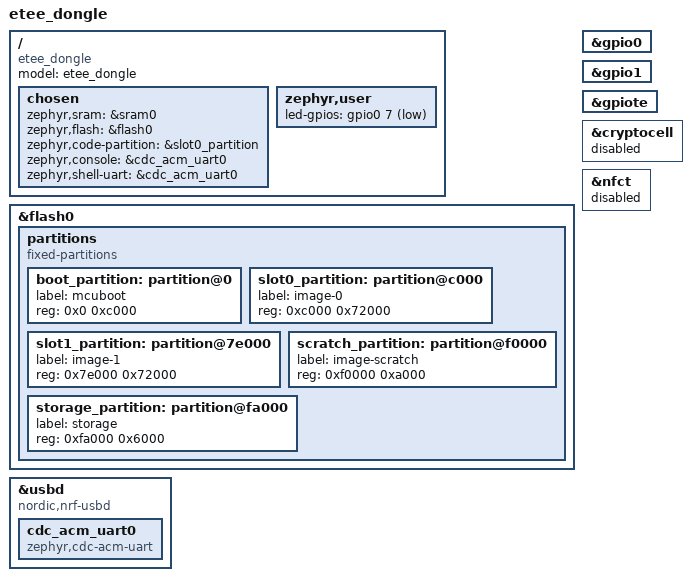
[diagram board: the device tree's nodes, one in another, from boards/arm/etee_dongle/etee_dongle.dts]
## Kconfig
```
#
# Copyright (c) 2020 Nordic Semiconductor
#
# SPDX-License-Identifier: LicenseRef-Nordic-5-Clause
#

source "Kconfig.zephyr"

menu "SlimeNRF"

endmenu
```

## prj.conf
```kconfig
#
# Copyright (c) 2019 Nordic Semiconductor ASA
#
# SPDX-License-Identifier: LicenseRef-Nordic-5-Clause
#
CONFIG_NCS_SAMPLES_DEFAULTS=y
CONFIG_ESB=y
CONFIG_NEWLIB_LIBC=y
CONFIG_CBPRINTF_FP_SUPPORT=y

CONFIG_USB_DEVICE_STACK=y
CONFIG_USB_DEVICE_HID=y
CONFIG_USB_DEVICE_MANUFACTURER="SlimeVR"
CONFIG_USB_DEVICE_VID=0x1209
CONFIG_USB_DEVICE_PID=0x7690
CONFIG_USB_HID_BOOT_PROTOCOL=y
CONFIG_USB_DEVICE_INITIALIZE_AT_BOOT=n
CONFIG_USB_CDC_ACM=y
CONFIG_UART_INTERRUPT_DRIVEN=y 

CONFIG_SERIAL=y
CONFIG_CONSOLE=y
CONFIG_UART_CONSOLE=y
CONFIG_UART_LINE_CTRL=y

CONFIG_LOG=y
CONFIG_USB_DRIVER_LOG_LEVEL_WRN=y
CONFIG_USB_DEVICE_LOG_LEVEL_WRN=y

CONFIG_LOG_BACKEND_UART=y
CONFIG_LOG_MODE_DEFERRED=y
#CONFIG_LOG_MODE_IMMEDIATE=y

CONFIG_CONSOLE_SUBSYS=y
CONFIG_CONSOLE_GETLINE=y

CONFIG_NVS_LOG_LEVEL_WRN=y
CONFIG_USB_HID_LOG_LEVEL_WRN=y

CONFIG_USB_DEVICE_SOF=y
CONFIG_USB_HID_REPORTS=256

#CONFIG_USB_HID_POLL_INTERVAL_MS=1
CONFIG_USB_HID_POLL_INTERVAL_MS=0
CONFIG_HID_INTERRUPT_EP_MPS=64
#CONFIG_ENABLE_HID_INT_OUT_EP=y

CONFIG_GPIO=y

CONFIG_NVS=y

CONFIG_FLASH=y
CONFIG_FLASH_PAGE_LAYOUT=y
CONFIG_FLASH_MAP=y

CONFIG_SETTINGS=y
CONFIG_SETTINGS_NVS=y
CONFIG_SETTINGS_RUNTIME=y

CONFIG_MPU_ALLOW_FLASH_WRITE=y

CONFIG_NVS_LOOKUP_CACHE=y

CONFIG_ESB_TX_FIFO_SIZE=1
CONFIG_NRFX_TIMER1=y

#speed up boot? (use internal rc oscillator)
#CONFIG_CLOCK_CONTROL_NRF_K32SRC_RC=y
#speed up boot? (synthesize lf clock)
CONFIG_CLOCK_CONTROL_NRF_K32SRC_SYNTH=y

# dont need it
CONFIG_CRYPTO=n
```

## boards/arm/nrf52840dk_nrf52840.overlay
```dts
/ {
	zephyr,user {
		led-gpios = <&gpio0 13 (GPIO_ACTIVE_LOW | GPIO_OPEN_DRAIN)>;
	};
};
```

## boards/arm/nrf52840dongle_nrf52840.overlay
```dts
/ {
	zephyr,user {
		led-gpios = <&gpio0 6 (GPIO_ACTIVE_LOW | GPIO_OPEN_DRAIN)>;
	};
};
```

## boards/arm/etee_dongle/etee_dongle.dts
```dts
// Copyright (c) 2024 Nordic Semiconductor ASA
// SPDX-License-Identifier: Apache-2.0

/dts-v1/;
#include <nordic/nrf52840_qiaa.dtsi>

/ {
	model = "etee_dongle";
	compatible = "etee_dongle";

	chosen {
		zephyr,sram = &sram0;
		zephyr,flash = &flash0;
		zephyr,code-partition = &slot0_partition;
		zephyr,console = &cdc_acm_uart0;
		zephyr,shell-uart = &cdc_acm_uart0;
	};

	zephyr,user {
		led-gpios = <&gpio0 7 (GPIO_ACTIVE_LOW | GPIO_OPEN_DRAIN)>;
		// red 0.07, green 1.15, blue 1.09
	};
};

&flash0 {
	partitions {
		compatible = "fixed-partitions";
		#address-cells = <1>;
		#size-cells = <1>;

		boot_partition: partition@0 {
			label = "mcuboot";
			reg = <0x0 0xc000>;
		};
		slot0_partition: partition@c000 {
			label = "image-0";
			reg = <0xc000 0x72000>;
		};
		slot1_partition: partition@7e000 {
			label = "image-1";
			reg = <0x7e000 0x72000>;
		};
		scratch_partition: partition@f0000 {
			label = "image-scratch";
			reg = <0xf0000 0xa000>;
		};
		storage_partition: partition@fa000 {
			label = "storage";
			reg = <0xfa000 0x6000>;
		};
	};
};

&gpio0 {
	status = "okay";
};

&gpio1 {
	status = "okay";
};

&gpiote {
	status = "okay";
};

zephyr_udc0: &usbd {
	compatible = "nordic,nrf-usbd";
	status = "okay";
	cdc_acm_uart0: cdc_acm_uart0 {
		compatible = "zephyr,cdc-acm-uart";
	};
};

&cryptocell {
	status = "disabled";
};

&nfct {
	status = "disabled";
};
```

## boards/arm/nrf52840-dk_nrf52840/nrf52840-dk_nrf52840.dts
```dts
// Copyright (c) 2024 Nordic Semiconductor ASA
// SPDX-License-Identifier: Apache-2.0

/dts-v1/;
#include <nordic/nrf52840_qiaa.dtsi>

/ {
	model = "nrf52840-dk_nrf52840";
	compatible = "nrf52840-dk_nrf52840";

	chosen {
		zephyr,sram = &sram0;
		zephyr,flash = &flash0;
		zephyr,code-partition = &slot0_partition;
	};

	zephyr,user {
		led-gpios = <&gpio0 13 (GPIO_ACTIVE_LOW | GPIO_OPEN_DRAIN)>;
	};
};

&flash0 {
	partitions {
		compatible = "fixed-partitions";
		#address-cells = <1>;
		#size-cells = <1>;

		// use original partitioning to keep nvs
		boot_partition: partition@0 {
			label = "mcuboot";
			reg = <0x00000000 0x0000C000>;
		};
		slot0_partition: partition@c000 {
			label = "image-0";
			reg = <0x0000C000 0x00076000>;
		};
		slot1_partition: partition@82000 {
			label = "image-1";
			reg = <0x00082000 0x00076000>;
		};
		storage_partition: partition@f8000 {
			label = "storage";
			reg = <0x000f8000 0x00008000>;
		};
	};
};

&usbd {
	status = "okay";
};

&gpio0 {
	status = "okay";
};

&gpiote {
	status = "okay";
};
```

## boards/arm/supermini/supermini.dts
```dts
// Copyright (c) 2024 Nordic Semiconductor ASA
// SPDX-License-Identifier: Apache-2.0

/dts-v1/;
#include <nordic/nrf52840_qiaa.dtsi>

/ {
	model = "supermini";
	compatible = "supermini";

	chosen {
		zephyr,sram = &sram0;
		zephyr,flash = &flash0;
		zephyr,code-partition = &slot0_partition;
		zephyr,console = &cdc_acm_uart0;
		zephyr,shell-uart = &cdc_acm_uart0;
	};

	// Uncomment below to Enable SW0
	// buttons {
	// 	compatible = "gpio-keys";
	// 	button0: button_0 {
	// 		gpios = <&gpio0 20 (GPIO_PULL_UP | GPIO_ACTIVE_LOW)>;
	// 		label = "Push button switch 0";
	// 	};
	// };

	// aliases {
	// 	sw0 = &button0;
	// };

	zephyr,user {
		led-gpios = <&gpio0 15 GPIO_OPEN_SOURCE>;
	};
};

&flash0 {
	partitions {
		compatible = "fixed-partitions";
		#address-cells = <1>;
		#size-cells = <1>;

		boot_partition: partition@0 {
			label = "mcuboot";
			reg = <0x0 0xc000>;
		};
		slot0_partition: partition@c000 {
			label = "image-0";
			reg = <0xc000 0x72000>;
		};
		slot1_partition: partition@7e000 {
			label = "image-1";
			reg = <0x7e000 0x72000>;
		};
		scratch_partition: partition@f0000 {
			label = "image-scratch";
			reg = <0xf0000 0xa000>;
		};
		storage_partition: partition@fa000 {
			label = "storage";
			reg = <0xfa000 0x6000>;
		};
	};
};

&gpio0 {
	status = "okay";
};

&gpiote {
	status = "okay";
};

zephyr_udc0: &usbd {
	compatible = "nordic,nrf-usbd";
	status = "okay";
	cdc_acm_uart0: cdc_acm_uart0 {
		compatible = "zephyr,cdc-acm-uart";
	};
};

&cryptocell {
	status = "disabled";
};

&nfct {
	status = "disabled";
};
```

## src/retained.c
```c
/*
 * Copyright (c) 2021 Nordic Semiconductor ASA
 *
 * SPDX-License-Identifier: Apache-2.0
 */

#include <string.h>
#include <zephyr/kernel.h>
#include <zephyr/devicetree.h>
#include <zephyr/sys/byteorder.h>
#include <zephyr/sys/crc.h>
#include <hal/nrf_power.h>
#include "retained.h"

/* nRF52 RAM (really, RAM AHB slaves) are partitioned as:
 * * Up to 8 blocks of two 4 KiBy byte "small" sections
 * * A 9th block of with 32 KiBy "large" sections
 *
 * At time of writing the maximum number of large sections is 6, all
 * within the first large block.  Theoretically there could be more
 * sections in the 9th block, and possibly more blocks.
 */

/* Inclusive address of RAM start */
#define SRAM_BEGIN (uintptr_t)DT_REG_ADDR(DT_NODELABEL(sram0))

/* Exclusive address of RAM end */
#define SRAM_END (SRAM_BEGIN + (uintptr_t)DT_REG_SIZE(DT_NODELABEL(sram0)))

/* Size of a controllable RAM section in the small blocks */
#define SMALL_SECTION_SIZE 4096

/* Number of controllable RAM sections in each of the lower blocks */
#define SMALL_SECTIONS_PER_BLOCK 2

/* Span of a small block */
#define SMALL_BLOCK_SIZE (SMALL_SECTIONS_PER_BLOCK * SMALL_SECTION_SIZE)

/* Number of small blocks */
#define SMALL_BLOCK_COUNT 8

/* Span of the SRAM area covered by small sections */
#define SMALL_SECTION_SPAN (SMALL_BLOCK_COUNT * SMALL_BLOCK_SIZE)

/* Inclusive address of the RAM range covered by large sections */
#define LARGE_SECTION_BEGIN (SRAM_BEGIN + SMALL_SECTION_SPAN)

/* Size of a controllable RAM section in large blocks */
#define LARGE_SECTION_SIZE 32768

/* Set or clear RAM retention in SYSTEM_OFF for the provided object.
 *
 * @note This only works for nRF52 with the POWER module.  The other
 * Nordic chips use a different low-level API, which is not currently
 * used by this function.
 *
 * @param ptr pointer to the start of the retainable object
 *
 * @param len length of the retainable object
 *
 * @param enable true to enable retention, false to clear retention
 */
int ram_range_retain(const void *ptr,
			    size_t len,
			    bool enable)
{
	uintptr_t addr = (uintptr_t)ptr;
	uintptr_t addr_end = addr + len;

	/* Error if the provided range is empty or doesn't lie
	 * entirely within the SRAM address space.
	 */
	if ((len == 0U)
	    || (addr < SRAM_BEGIN)
	    || (addr > (SRAM_END - len))) {
		return -EINVAL;
	}

	/* Iterate over each section covered by the range, setting the
	 * corresponding RAM OFF retention bit in the parent block.
	 */
	do {
		uintptr_t block_base = SRAM_BEGIN;
		uint32_t section_size = SMALL_SECTION_SIZE;
		uint32_t sections_per_block = SMALL_SECTIONS_PER_BLOCK;
		bool is_large = (addr >= LARGE_SECTION_BEGIN);
		uint8_t block = 0;

		if (is_large) {
			block = 8;
			block_base = LARGE_SECTION_BEGIN;
			section_size = LARGE_SECTION_SIZE;

			/* RAM[x] supports only 16 sections, each its own bit
			 * for POWER (0..15) and RETENTION (16..31).  We don't
			 * know directly how many sections are present, so
			 * assume they all are; the true limit will be
			 * determined by the SRAM size.
			 */
			sections_per_block = 16;
		}

		uint32_t section = (addr - block_base) / section_size;

		if (section >= sections_per_block) {
			block += section / sections_per_block;
			section %= sections_per_block;
		}

		uint32_t section_mask =
			(POWER_RAM_POWERSET_S0RETENTION_On
					 << (section + POWER_RAM_POWERSET_S0RETENTION_Pos));

		if (enable) {
			nrf_power_rampower_mask_on(NRF_POWER, block, section_mask);
		} else {
			nrf_power_rampower_mask_off(NRF_POWER, block, section_mask);
		}

		/* Move to the first address in the next section. */
		addr += section_size - (addr % section_size);
	} while (addr < addr_end);

	return 0;
}
```

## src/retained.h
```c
/*
 * Copyright (c) 2021 Nordic Semiconductor ASA
 *
 * SPDX-License-Identifier: Apache-2.0
 */

#ifndef RETAINED_H_
#define RETAINED_H_

#include <inttypes.h>

int ram_range_retain(const void *ptr, size_t len, bool enable);

#endif /* RETAINED_H_ */
```
